# PAC52XX register map
Vendor: Active-Semi; Series: PAC52XX; File version: 1.0
CPU: CM0 r0p0, little endian, no MPU, no FPU, vendor SysTick, 2 interrupt priority bits
Registers are 32-bit, read-write, reset 0x0 unless marked. A register's access mark holds for its fields unless they carry their own. Offsets are from the block's base; [hi:lo] are bit positions; {n}, {i} and the like mark numbered series; 'fields as' and 'values as' point back to an identical list.

## GPIOA — General-Purpose Input-Output Port A
Base 0x40070000
Same registers: GPIOB 0x40070040, GPIOD 0x40080040, GPIOE 0x40090000
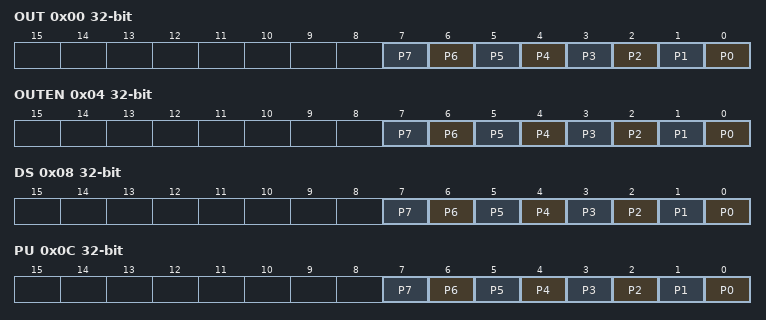
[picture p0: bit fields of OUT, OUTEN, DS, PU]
0x00 OUT — GPIO Port Output
  [n] P{n} (n=0..7) — Port output {n}
    0=low (Set output low if GPIOn->OUTEN.P{n} = 1); 1=high (Set output high if GPIOn->OUTEN.P{n} = 1)
0x04 OUTEN — GPIO Port Output Enable
  [n] P{n} (n=0..7) — Port output enable {n}
    0=low (Output disabled, high-impedance state); 1=high (Output state set by GPIOn->OUT.P{n})
0x08 DS — GPIO Port Output Drive Strength Select
  [all] fields
    0=low (Low output drive strength selected); 1=High output drive strength selected
  [n] P{n} (n=0..7) — Port output drive strength select {n}
0x0C PU — GPIO Port Weak Pull Up
  [all] fields
    0=disabled (Weak pull-up disabled); 1=enabled (Weak pull-up to VCCIO enabled)
  [n] P{n} (n=0..7) — Port<n>{n} weak pull-up select
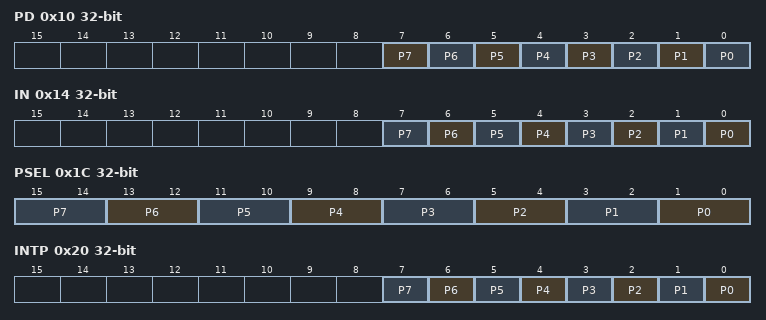
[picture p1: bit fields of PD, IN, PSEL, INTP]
0x10 PD — GPIO Port Weak Pull Down
  [all] fields
    0=disabled (Weak pull-down disabled); 1=enabled (Weak pull-down to VSS enabled)
  [7] P7 — Port<n>7 weak pull-down select
  [6] P6 — Port<n>6 weak pull-down select
  [5] P5 — Port<n>0 weak pull-down select
  [n] P{n} (n=0..4) — Port<n>{n} weak pull-down select
0x14 IN ro — GPIO Port Input
  [all] fields
    0=low (Logic low); 1=high (Logic high)
  [n] P{n} (n=0..7) — Port<n>{n} input state
0x1C PSEL — GPIO Peripheral Select
  [all] fields
    0=IO (Port in I/O mode); 1=Peripheral 1 (Peripheral Configuration 1); 2=Peripheral 2 (Peripheral Configuration 2); 3=Peripheral 3 (Peripheral Configuration 3)
  [2n+1:2n] P{n} (n=0..7) — Port<n>{n} peripheral select
0x20 INTP — GPIO Port Interrupt Polarity
  [all] fields
    0=Falling edge, high to low transition; 1=Rising edge, low to high transition
  [n] P{n} (n=0..7) — Port<n>{n} Interrupt Polarity
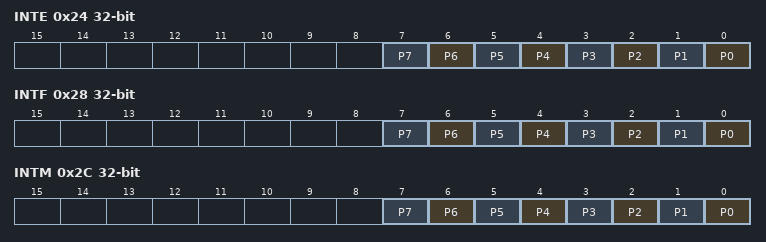
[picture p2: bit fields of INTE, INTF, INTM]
0x24 INTE — GPIO Port Interrupt Enable
  [all] fields
    0=Disable interrupt; 1=Enable interrupt
  [n] P{n} (n=0..7) — Port<n>{n} Interrupt Enable
0x28 INTF rw-once — GPIO Port Interrupt Flag
  [all] fields
    0=none (No interrupt pending); 1=Interrupt pending
  [n] P{n} (n=0..7) — Port<n>{n} Interrupt
0x2C INTM — GPIO Port Interrupt Mask
  [all] fields
    0=disabled (Disable interrupt mask); 1=enabled (Enable interrupt mask)
  [n] P{n} (n=0..7) — Port<n>{n} Interrupt Mask

## GPIOC — General-Purpose Input-Output Port C
Base 0x40080000
Registers as GPIOA, without DS, PU, PD, PSEL; these are added or differ:
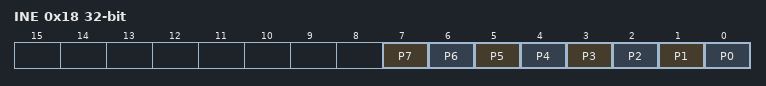
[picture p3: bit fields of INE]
0x18 INE — GPIO Port Input Enable
  [n] P{n} (n=3..7) — Port input enable {n}
    0=disabled (Input disabled); 1=enabled (Input enabled, for I/O operation)
  [2] P2 — Port input enable 2
    0=disabled (Input disabled); 1=high (Input enabled, for I/O operation)
  [1] P1 — Port input enable 1
    values as P3
  [0] P0 — Port input enable 0
    values as P3

## UART
Base 0x401D0000
0x00 UARTRXTX — UART receive/transmit FIFO
  [7:0] RXTX — Receive and Transmit FIFO buffer (read: RX FIFO, write: TX FIFO)
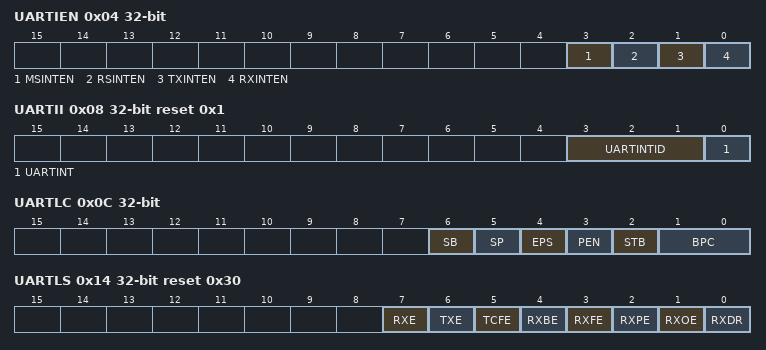
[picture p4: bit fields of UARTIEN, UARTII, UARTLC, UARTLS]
0x04 UARTIEN — UART interrupt enable
  [all] fields
    0=disable interrupt; 1=enable interrupt
  [3] MSINTEN — Model Status interrupt enable
  [2] RSINTEN — Receive interrupt enable
  [1] TXINTEN — TX register data available interrupt enable
  [0] RXINTEN — RX register data available interrupt enable
0x08 UARTII reset 0x1 — UART interrupt identification
  [3:1] UARTINTID — UART interrupt type
    0=modem status; 1=TX hold register empty; 2=RX data available; 3=RX line status; 6=Timeout
  [0] UARTINT — UART interrupt
    0=disable interrupt; 1=enable interrupt
0x0C UARTLC — UART Line Control
  [6] SB — Break control
    0=normal operation; 1=force TX to 0
  [5] SP — Stick parity
    0=disable; 1=enable
  [4] EPS — Parity type
    0=odd (generate ODD parity); 1=even (generate EVEN parity)
  [3] PEN — Parity enable
    0=disabled (parity disabled); 1=enabled (parity enabled)
  [2] STB — Stop bits
    0=1 stop bit; 1=2 stop bits (1.5 if BPC=00b)
  [1:0] BPC — Bit per character
    {v}={v+5} bits (v=0..3)
0x14 UARTLS reset 0x30 — UART Line Status
  [7] RXE — RX FIFO error
    0=no error in RX FIFO; 1=error (At least one parity, framing or break error active in FIFO)
  [6] TXE — TX empty
    0=cleared (error cleared); 1=error (TX shift register and TX FIFO are empty)
  [5] TCFE — TX FIFO empty
    0=cleared (error cleared); 1=error (TX FIFO is empty)
  [4] RXBE — RX break error
    0=cleared (error cleared); 1=error (entry on top of RX FIFO has break error, cleared on read)
  [3] RXFE — RX framing error
    0=cleared (error cleared); 1=error (entry on top of RX FIFO has framing error, cleared on read)
  [2] RXPE — RX parity error
    0=cleared (error cleared); 1=error (entry on top of RX FIFO has parity error, cleared on read)
  [1] RXOE — RX overrun error
    0=cleared (error cleared); 1=full (RX FIFO full and last entry overwritten, cleared on read)
  [0] RXDR — RX data ready
    0=empty (RX FIFO empty); 1=not empty (At least one entry in RX FIFO)
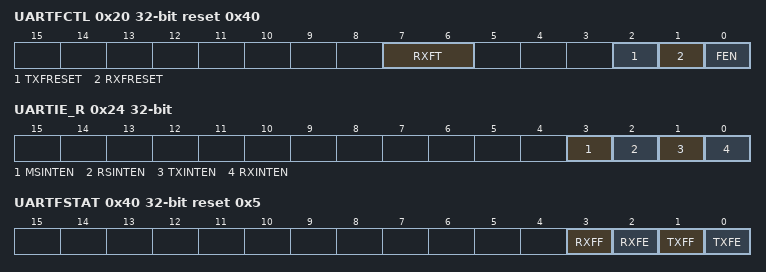
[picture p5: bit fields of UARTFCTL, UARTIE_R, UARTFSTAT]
0x20 UARTFCTL reset 0x40 — FIFO control
  [7:6] RXFT — RX FIFO Theshold
    0=1 byte in FIFO; 1=4 bytes in FIFO; 2=8 bytes in FIFO; 3=14 bytes in FIFO
  [2] TXFRESET — RX FIFO reset
    0=no action; 1=clear TX FIFO, cleared on read
  [1] RXFRESET — RX FIFO reset
    0=no action; 1=clear RX FIFO, cleared on read
  [0] FEN — FIFO enable
    0=disabled (disable RX, TX FIFO); 1=enabled (enable RX, TX FIFO)
0x24 UARTIE_R — UART interrupt enable remapped
  [all] fields
    0=disabled (disable interrupt); 1=enabled (enable interrupt)
  [3] MSINTEN — Modem status interrupt enable
  [2] RSINTEN — Receive interrupt enable
  [1] TXINTEN — TX register data available interrupt enable
  [0] RXINTEN — RX register data available interrupt enable
0x28 UARTDL_L — UART divisor latch low byte
  [7:0] DL_L — RX register data available interrupt enable
0x2C UARTDL_H — UART divisor latch high byte
  [7:0] DL_H — Divisor value, high byte
0x38 UARTFD_F — UART fractional divisor value
  [7:0] FRAC — Fractional divisor value
0x40 UARTFSTAT reset 0x5 — UART FIFO status
  [3] RXFF — RX FIFO full
    0=not full (RX FIFO not full); 1=full (RX FIFO full)
  [2] RXFE — RX FIFO empty
    0=not empty (RX FIFO not empty); 1=empty (RX FIFO empty)
  [1] TXFF — TX FIFO full
    0=not full (TX FIFO not full); 1=full (TX FIFO full)
  [0] TXFE — TX FIFO empty
    0=not empty (TX FIFO not empty); 1=empty (TX FIFO empty)

## SOCB — SOC Bus Bridge
Base 0x40200000
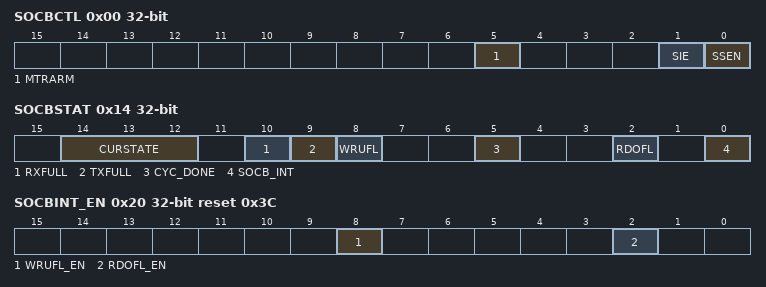
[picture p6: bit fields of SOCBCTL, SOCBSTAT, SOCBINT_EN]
0x00 SOCBCTL — SOC Bus Bridge Control
  [5] MTRARM wo — MTRANS re-arm
    1=re-arms the SOCBCTL.MTRANS operation by de-asserting CSx chip select and returning the master mode state machine to IDLE
  [1] SIE — SOC bus bridge interrupt enable
    0=disable interrupts; 1=enable interrupts
  [0] SSEN — SOC bus bridge enable
    0=disable this module; 1=enable this module
0x04 SOCBCFG — SOC Bus Bridge Configuration
  [2] MRST — Module reset
    0=disable (do not hold the module in reset); 1=reset (force soft reset of module. The internal state machines are reset; status register is cleared; however, the soft reset does not affect control register values.)
0x14 SOCBSTAT — SOC Bus Bridge Status
  [14:12] CURSTATE — Raw status of the SOC bus bridge master state machine's 'current_state' register
    0=IDLE; 1=CSSETUP; 2=TRANSFER; 3=CSHOLD; 4=CSWAIT; 5=CKWAIT; 6=MTRANS; 7=CSBEGIN
  [10] RXFULL — Receive holding register in use
    0=empty (RX incoming holding register contains no valid data word); 1=full (RX incoming holding register contains a valid data word)
  [9] TXFULL — Transmit holding register in use
    0=ready (TX transmit holding register ready to accept data word); 1=not ready (TX transmit holding register in use and not ready)
  [8] WRUFL — Write buffer underflow
    0=none (No write buffer underflow detected since this bit was cleared); 1=underflow (Write buffer underflow detected, write one to clear)
  [5] CYC_DONE — Cycle done (current transfer is complete)
    0=not done (No cycle done detected since this bit was cleared); 1=completed (Cycle done detected, write one to clear)
  [2] RDOFL — Read buffer overflow
    0=none (no read overflow since bit cleared); 1=overflow (read overflow detected, write 1 to clear)
  [0] SOCB_INT — SOC bus bridge interrupt
    0=none (no interrupt); 1=interrupt
0x1C SOCBD — SOC Bus Bridge Data. On READ, retrieve received data word from the incoming holding buffer. On WRITE, write address or data word to the outgoing holding buffer
  [7:0] DATA — SOC bus bridge data
0x20 SOCBINT_EN reset 0x3C — SOC Bus Bridge Interrupt Enable
  [8] WRUFL_EN — Write buffer underflow SOCBSTAT.WRUFL interrupt enable
    0=disable SOCBSTAT.WRUFL interrupt; 1=enable SOCBSTAT.WRUFL interrupt
  [2] RDOFL_EN — Read buffer overflow RDOFL interrupt enable
    0=disable SOCBSTAT.RDOFL interrupt; 1=enable SOCBSTAT.RDOFL interrupt
